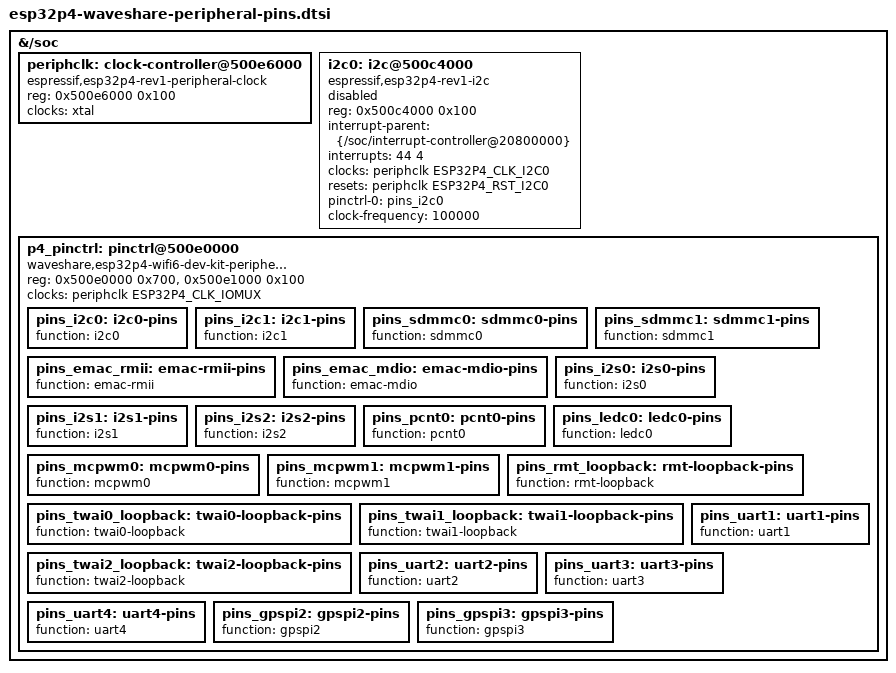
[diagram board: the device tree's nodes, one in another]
// SPDX-License-Identifier: (GPL-2.0-only OR BSD-2-Clause)
#include <dt-bindings/clock/esp32p4-peripheral-clock.h>

&{/soc} {
	periphclk: clock-controller@500e6000 {
		compatible = "espressif,esp32p4-rev1-peripheral-clock";
		reg = <0x500e6000 0x100>;
		clocks = <&xtal>;
		#clock-cells = <1>;
		#reset-cells = <1>;
	};

	/* TRM ch.48 I2C Controller — HP I2C0 master and IRQ44. */
	i2c0: i2c@500c4000 {
		compatible = "espressif,esp32p4-rev1-i2c";
		reg = <0x500c4000 0x100>;
		interrupt-parent = <&{/soc/interrupt-controller@20800000}>;
		interrupts = <44 4>;
		clocks = <&periphclk ESP32P4_CLK_I2C0>;
		resets = <&periphclk ESP32P4_RST_I2C0>;
		pinctrl-names = "default";
		pinctrl-0 = <&pins_i2c0>;
		clock-frequency = <100000>;
		#address-cells = <1>;
		#size-cells = <0>;
		/* I2C1 owns the display pads by default. */
		status = "disabled";
	};

	p4_pinctrl: pinctrl@500e0000 {
		compatible = "waveshare,esp32p4-wifi6-dev-kit-peripheral-pinctrl";
		reg = <0x500e0000 0x700>, <0x500e1000 0x100>;
		clocks = <&periphclk ESP32P4_CLK_IOMUX>;

		pins_i2c0: i2c0-pins {
			function = "i2c0";
		};

		pins_i2c1: i2c1-pins {
			function = "i2c1";
		};

		pins_sdmmc0: sdmmc0-pins {
			function = "sdmmc0";
		};

		pins_sdmmc1: sdmmc1-pins {
			function = "sdmmc1";
		};

		pins_emac_rmii: emac-rmii-pins {
			function = "emac-rmii";
		};

		pins_emac_mdio: emac-mdio-pins {
			function = "emac-mdio";
		};

		pins_i2s0: i2s0-pins {
			function = "i2s0";
		};

		pins_i2s1: i2s1-pins {
			function = "i2s1";
		};

		pins_i2s2: i2s2-pins {
			function = "i2s2";
		};

		pins_pcnt0: pcnt0-pins {
			function = "pcnt0";
		};

		pins_ledc0: ledc0-pins {
			function = "ledc0";
		};

		pins_mcpwm0: mcpwm0-pins {
			function = "mcpwm0";
		};

		pins_mcpwm1: mcpwm1-pins {
			function = "mcpwm1";
		};

		pins_rmt_loopback: rmt-loopback-pins {
			function = "rmt-loopback";
		};

		pins_twai0_loopback: twai0-loopback-pins {
			function = "twai0-loopback";
		};

		pins_twai1_loopback: twai1-loopback-pins {
			function = "twai1-loopback";
		};

		pins_twai2_loopback: twai2-loopback-pins {
			function = "twai2-loopback";
		};

		pins_uart1: uart1-pins {
			function = "uart1";
		};

		pins_uart2: uart2-pins {
			function = "uart2";
		};

		pins_uart3: uart3-pins {
			function = "uart3";
		};

		pins_uart4: uart4-pins {
			function = "uart4";
		};

		pins_gpspi2: gpspi2-pins {
			function = "gpspi2";
		};

		pins_gpspi3: gpspi3-pins {
			function = "gpspi3";
		};
	};
};
